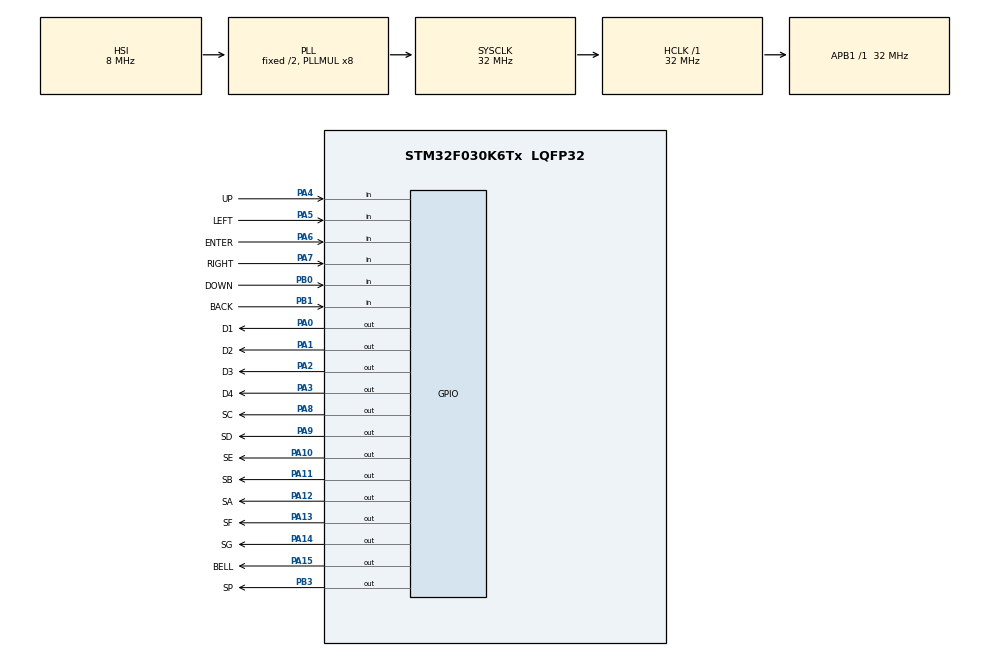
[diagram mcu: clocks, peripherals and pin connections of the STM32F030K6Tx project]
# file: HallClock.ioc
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Mcu.Family=STM32F0
Mcu.Name=STM32F030K6Tx
Mcu.Package=LQFP32
PA0.GPIO_Label=D1
PA0.Signal=GPIO_Output
PA1.GPIO_Label=D2
PA1.Signal=GPIO_Output
PA10.GPIO_Label=SE
PA10.Signal=GPIO_Output
PA11.GPIO_Label=SB
PA11.Signal=GPIO_Output
PA12.GPIO_Label=SA
PA12.Signal=GPIO_Output
PA13.GPIO_Label=SF
PA13.Signal=GPIO_Output
PA14.GPIO_Label=SG
PA14.Signal=GPIO_Output
PA15.GPIO_Label=BELL
PA15.Signal=GPIO_Output
PA2.GPIO_Label=D3
PA2.Signal=GPIO_Output
PA3.GPIO_Label=D4
PA3.Signal=GPIO_Output
PA4.GPIO_Label=UP
PA4.Signal=GPIO_Input
PA5.GPIO_Label=LEFT
PA5.Signal=GPIO_Input
PA6.GPIO_Label=ENTER
PA6.Signal=GPIO_Input
PA7.GPIO_Label=RIGHT
PA7.Signal=GPIO_Input
PA8.GPIO_Label=SC
PA8.Signal=GPIO_Output
PA9.GPIO_Label=SD
PA9.Signal=GPIO_Output
PB0.GPIO_Label=DOWN
PB0.Signal=GPIO_Input
PB1.GPIO_Label=BACK
PB1.Signal=GPIO_Input
PB3.GPIO_Label=SP
PB3.Signal=GPIO_Output
PF0-OSC_IN.Mode=HSE-External-Oscillator
PF0-OSC_IN.Signal=RCC_OSC_IN
PF1-OSC_OUT.Mode=HSE-External-Oscillator
PF1-OSC_OUT.Signal=RCC_OSC_OUT
ProjectManager.HeapSize=0x200
ProjectManager.StackSize=0x400
ProjectManager.TargetToolchain=SW4STM32
RCC.AHBFreq_Value=32000000
RCC.APB1Freq_Value=32000000
RCC.APB1TimFreq_Value=32000000
RCC.HCLKFreq_Value=32000000
RCC.HSE_VALUE=7372800
RCC.PLLMUL=RCC_PLL_MUL8
RCC.RTCClockSelection=RCC_RTCCLKSOURCE_HSE_DIV32
RCC.SYSCLKFreq_VALUE=32000000
RCC.SYSCLKSource=RCC_SYSCLKSOURCE_PLLCLK
RTC.Format=RTC_FORMAT_BIN
RTC.SynchPrediv=1799
VP_RTC_VS_RTC_Activate.Mode=RTC_Enabled
VP_RTC_VS_RTC_Calendar.Mode=RTC_Calendar
board=custom

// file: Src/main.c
/* USER CODE BEGIN Header */
/**
  ******************************************************************************
  * @file           : main.c
  * @brief          : Main program body
  ******************************************************************************
  * @attention
  *
  * <h2><center>&copy; Copyright (c) 2019 STMicroelectronics.
  * All rights reserved.</center></h2>
  *
  * This software component is licensed by ST under BSD 3-Clause license,
  * the "License"; You may not use this file except in compliance with the
  * License. You may obtain a copy of the License at:
  *                        opensource.org/licenses/BSD-3-Clause
  *
  ******************************************************************************
  */
/* USER CODE END Header */

#include "main.h"

/* USER CODE BEGIN Includes */
#include "sevenseg.h"
#include "rtc.h"
/* USER CODE END Includes */

RTC_HandleTypeDef hrtc;

/* USER CODE BEGIN PV */
int alarm[4][2];

int modeSelected = 0;
int modeActual = 0;
//^modes - 0 display, 1 set alarm, 2 set clock,

int actuallySetting;

/* USER CODE END PV */

void SystemClock_Config(void);
static void MX_GPIO_Init(void);
static void MX_RTC_Init(void);

int main(void)
{

  /* MCU Configuration--------------------------------------------------------*/

  /* Reset of all peripherals, Initializes the Flash interface and the Systick. */
  HAL_Init();

  /* Configure the system clock */
  SystemClock_Config();

  /* Initialize all configured peripherals */
  MX_GPIO_Init();
  MX_RTC_Init();

  /* Infinite loop */
  /* USER CODE BEGIN WHILE */
  while (1)
  {

	 display(1, 8);
	 display(2, 8);
	 display(3, 8);
	 display(4, 8);
	  HAL_GPIO_WritePin(BELL_GPIO_Port, BELL_Pin, 1);
	  HAL_Delay(1000);
	  HAL_GPIO_WritePin(BELL_GPIO_Port, BELL_Pin, 0);
	  HAL_Delay(1000);

    /* USER CODE END WHILE */

  }
}

void SystemClock_Config(void)
{
  RCC_OscInitTypeDef RCC_OscInitStruct = {0};
  RCC_ClkInitTypeDef RCC_ClkInitStruct = {0};
  RCC_PeriphCLKInitTypeDef PeriphClkInit = {0};

  /** Initializes the CPU, AHB and APB busses clocks
  */
  RCC_OscInitStruct.OscillatorType = RCC_OSCILLATORTYPE_HSI|RCC_OSCILLATORTYPE_HSE;
  RCC_OscInitStruct.HSEState = RCC_HSE_ON;
  RCC_OscInitStruct.HSIState = RCC_HSI_ON;
  RCC_OscInitStruct.HSICalibrationValue = RCC_HSICALIBRATION_DEFAULT;
  RCC_OscInitStruct.PLL.PLLState = RCC_PLL_ON;
  RCC_OscInitStruct.PLL.PLLSource = RCC_PLLSOURCE_HSI;
  RCC_OscInitStruct.PLL.PLLMUL = RCC_PLL_MUL8;
  RCC_OscInitStruct.PLL.PREDIV = RCC_PREDIV_DIV1;
  if (HAL_RCC_OscConfig(&RCC_OscInitStruct) != HAL_OK)
  {
    Error_Handler();
  }
  /** Initializes the CPU, AHB and APB busses clocks
  */
  RCC_ClkInitStruct.ClockType = RCC_CLOCKTYPE_HCLK|RCC_CLOCKTYPE_SYSCLK
                              |RCC_CLOCKTYPE_PCLK1;
  RCC_ClkInitStruct.SYSCLKSource = RCC_SYSCLKSOURCE_PLLCLK;
  RCC_ClkInitStruct.AHBCLKDivider = RCC_SYSCLK_DIV1;
  RCC_ClkInitStruct.APB1CLKDivider = RCC_HCLK_DIV1;

  if (HAL_RCC_ClockConfig(&RCC_ClkInitStruct, FLASH_LATENCY_1) != HAL_OK)
  {
    Error_Handler();
  }
  PeriphClkInit.PeriphClockSelection = RCC_PERIPHCLK_RTC;
  PeriphClkInit.RTCClockSelection = RCC_RTCCLKSOURCE_HSE_DIV32;
  if (HAL_RCCEx_PeriphCLKConfig(&PeriphClkInit) != HAL_OK)
  {
    Error_Handler();
  }
}

static void MX_RTC_Init(void)
{

  RTC_TimeTypeDef sTime = {0};
  RTC_DateTypeDef sDate = {0};

  /** Initialize RTC Only
  */
  hrtc.Instance = RTC;
  hrtc.Init.HourFormat = RTC_HOURFORMAT_24;
  hrtc.Init.AsynchPrediv = 127;
  hrtc.Init.SynchPrediv = 1799;
  hrtc.Init.OutPut = RTC_OUTPUT_DISABLE;
  hrtc.Init.OutPutPolarity = RTC_OUTPUT_POLARITY_HIGH;
  hrtc.Init.OutPutType = RTC_OUTPUT_TYPE_OPENDRAIN;
  if (HAL_RTC_Init(&hrtc) != HAL_OK)
  {
    Error_Handler();
  }

  /** Initialize RTC and set the Time and Date
  */
  sTime.Hours = 0;
  sTime.Minutes = 0;
  sTime.Seconds = 0;
  sTime.DayLightSaving = RTC_DAYLIGHTSAVING_NONE;
  sTime.StoreOperation = RTC_STOREOPERATION_RESET;
  if (HAL_RTC_SetTime(&hrtc, &sTime, RTC_FORMAT_BIN) != HAL_OK)
  {
    Error_Handler();
  }
  sDate.WeekDay = RTC_WEEKDAY_MONDAY;
  sDate.Month = RTC_MONTH_JANUARY;
  sDate.Date = 1;
  sDate.Year = 0;

  if (HAL_RTC_SetDate(&hrtc, &sDate, RTC_FORMAT_BIN) != HAL_OK)
  {
    Error_Handler();
  }

}

static void MX_GPIO_Init(void)
{
  GPIO_InitTypeDef GPIO_InitStruct = {0};

  /* GPIO Ports Clock Enable */
  __HAL_RCC_GPIOF_CLK_ENABLE();
  __HAL_RCC_GPIOA_CLK_ENABLE();
  __HAL_RCC_GPIOB_CLK_ENABLE();

  /*Configure GPIO pin Output Level */
  HAL_GPIO_WritePin(GPIOA, D1_Pin|D2_Pin|D3_Pin|D4_Pin
                          |SE_Pin|SD_Pin|SC_Pin|SB_Pin, GPIO_PIN_RESET);

  /*Configure GPIO pin Output Level */
  HAL_GPIO_WritePin(GPIOB, SP_Pin|BELL_Pin|SA_Pin|SF_Pin
                          |SG_Pin, GPIO_PIN_RESET);

  /*Configure GPIO pins : D1_Pin D2_Pin D3_Pin D4_Pin
                           SE_Pin SD_Pin SC_Pin SB_Pin */
  GPIO_InitStruct.Pin = D1_Pin|D2_Pin|D3_Pin|D4_Pin
                          |SE_Pin|SD_Pin|SC_Pin|SB_Pin;
  GPIO_InitStruct.Mode = GPIO_MODE_OUTPUT_PP;
  GPIO_InitStruct.Pull = GPIO_NOPULL;
  GPIO_InitStruct.Speed = GPIO_SPEED_FREQ_LOW;
  HAL_GPIO_Init(GPIOA, &GPIO_InitStruct);

  /*Configure GPIO pins : SP_Pin BELL_Pin SA_Pin SF_Pin
                           SG_Pin */
  GPIO_InitStruct.Pin = SP_Pin|BELL_Pin|SA_Pin|SF_Pin
                          |SG_Pin;
  GPIO_InitStruct.Mode = GPIO_MODE_OUTPUT_PP;
  GPIO_InitStruct.Pull = GPIO_NOPULL;
  GPIO_InitStruct.Speed = GPIO_SPEED_FREQ_LOW;
  HAL_GPIO_Init(GPIOB, &GPIO_InitStruct);

  /*Configure GPIO pins : BACK_Pin ENTER_Pin DOWN_Pin RIGHT_Pin
                           LEFT_Pin UP_Pin */
  GPIO_InitStruct.Pin = BACK_Pin|ENTER_Pin|DOWN_Pin|RIGHT_Pin
                          |LEFT_Pin|UP_Pin;
  GPIO_InitStruct.Mode = GPIO_MODE_INPUT;
  GPIO_InitStruct.Pull = GPIO_NOPULL;
  HAL_GPIO_Init(GPIOA, &GPIO_InitStruct);

}

void Error_Handler(void)
{
}

/************************ (C) COPYRIGHT STMicroelectronics *****END OF FILE****/
